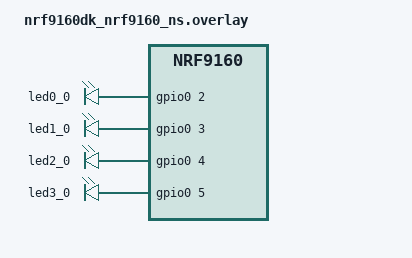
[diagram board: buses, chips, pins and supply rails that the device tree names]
/* Copyright (c) 2023 Nordic Semiconductor ASA
 *
 * SPDX-License-Identifier: LicenseRef-Nordic-5-Clause
 */

/ {
	/* Define 4 monochromatic LEDs connected directly
	 * to the GPIO to be used with CAF LEDs module
	 */
	led0 {
		compatible = "gpio-leds";
		status = "okay";

		led0_0: led_0 {
			gpios = <&gpio0 2 0>;
		};
	};

	led1 {
		compatible = "gpio-leds";
		status = "okay";

		led1_0: led_0 {
			gpios = <&gpio0 3 0>;
		};
	};

	led2 {
		compatible = "gpio-leds";
		status = "okay";

		led2_0: led_0 {
			gpios = <&gpio0 4 0>;
		};
	};

	led3 {
		compatible = "gpio-leds";
		status = "okay";

		led3_0: led_0 {
			gpios = <&gpio0 5 0>;
		};
	};

	/* Disable the original leds node from device-tree
	 * since it is incompatible with the CAF LEDs module
	 */
	leds {
		status = "disabled";
	};
};
